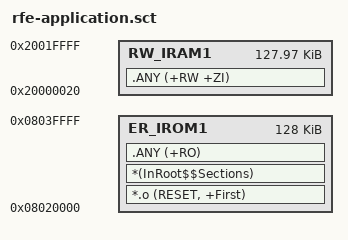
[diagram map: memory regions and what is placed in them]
;#! armcc -E
; marco.accame: so far i cannot successfully call the cpreprocessor in here without errors
; the above must be on teh first line of teh scatter file ...

; Copyright (C) 2011 Department of Robotics Brain and Cognitive Sciences - Istituto Italiano di Tecnologia
; Author:  Marco Accame
; email:   marco.accame@iit.it
; website: www.robotcub.org
; Permission is granted to copy, distribute, and/or modify this program
; under the terms of the GNU General Public License, version 2 or any
; later version published by the Free Software Foundation.
;
; A copy of the license can be found at
; http://www.robotcub.org/icub/license/gpl.txt
;
; This program is distributed in the hope that it will be useful, but
; WITHOUT ANY WARRANTY; without even the implied warranty of
; MERCHANTABILITY or FITNESS FOR A PARTICULAR PURPOSE. See the GNU General
; Public License for more details
; due to a bug in linker (in some older versions), you may need to put the whole path ... thus change it by hand
;#include "D:\#inhere\sdl\embedded\arm\embody\body\embenv\envcom\eEmemorymap.h"
;#include "..\..\cfg\eEmemorymap.h"


; flash starts from xx and its size is xxx
LR_IROM1 0x08020000 0x00020000  {    ; load region size_region  ; marco.accame: we have more than 128kb, but so fare they are enough.
  ER_IROM1 0x08020000 0x00020000  {  ; load address = execution address
   *.o (RESET, +First)
   *(InRoot$$Sections)
   .ANY (+RO)
  }
  RW_IRAM1 0x20000020 0x1FFE0  {  ; RW data ; marco.accame: we use only the first bank of 128kb w/out the first 32 bytes
   .ANY (+RW +ZI)
  }
}  




